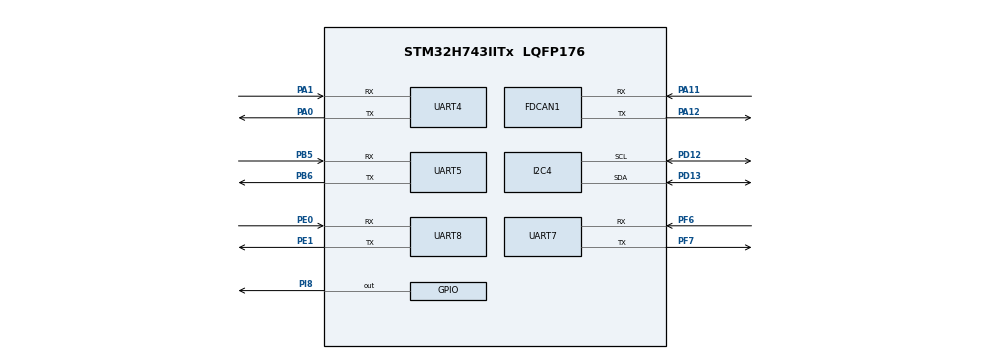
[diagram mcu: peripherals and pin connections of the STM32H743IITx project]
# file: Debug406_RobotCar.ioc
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CORTEX_M7.CPU_DCache=Disabled
CORTEX_M7.CPU_ICache=Disabled
Dma.Request0=UART4_TX
Dma.Request1=UART4_RX
Dma.UART4_RX.1.Direction=DMA_PERIPH_TO_MEMORY
Dma.UART4_RX.1.EventEnable=DISABLE
Dma.UART4_RX.1.FIFOMode=DMA_FIFOMODE_DISABLE
Dma.UART4_RX.1.Instance=DMA1_Stream1
Dma.UART4_RX.1.MemDataAlignment=DMA_MDATAALIGN_BYTE
Dma.UART4_RX.1.MemInc=DMA_MINC_ENABLE
Dma.UART4_RX.1.Mode=DMA_NORMAL
Dma.UART4_RX.1.PeriphDataAlignment=DMA_PDATAALIGN_BYTE
Dma.UART4_RX.1.PeriphInc=DMA_PINC_DISABLE
Dma.UART4_RX.1.Polarity=HAL_DMAMUX_REQ_GEN_RISING
Dma.UART4_RX.1.Priority=DMA_PRIORITY_LOW
Dma.UART4_RX.1.RequestNumber=1
Dma.UART4_RX.1.SignalID=NONE
Dma.UART4_RX.1.SyncEnable=DISABLE
Dma.UART4_RX.1.SyncPolarity=HAL_DMAMUX_SYNC_NO_EVENT
Dma.UART4_RX.1.SyncRequestNumber=1
Dma.UART4_RX.1.SyncSignalID=NONE
Dma.UART4_TX.0.Direction=DMA_MEMORY_TO_PERIPH
Dma.UART4_TX.0.EventEnable=DISABLE
Dma.UART4_TX.0.FIFOMode=DMA_FIFOMODE_DISABLE
Dma.UART4_TX.0.Instance=DMA1_Stream0
Dma.UART4_TX.0.MemDataAlignment=DMA_MDATAALIGN_BYTE
Dma.UART4_TX.0.MemInc=DMA_MINC_ENABLE
Dma.UART4_TX.0.Mode=DMA_NORMAL
Dma.UART4_TX.0.PeriphDataAlignment=DMA_PDATAALIGN_BYTE
Dma.UART4_TX.0.PeriphInc=DMA_PINC_DISABLE
Dma.UART4_TX.0.Polarity=HAL_DMAMUX_REQ_GEN_RISING
Dma.UART4_TX.0.Priority=DMA_PRIORITY_HIGH
Dma.UART4_TX.0.RequestNumber=1
Dma.UART4_TX.0.SignalID=NONE
Dma.UART4_TX.0.SyncEnable=DISABLE
Dma.UART4_TX.0.SyncPolarity=HAL_DMAMUX_SYNC_NO_EVENT
Dma.UART4_TX.0.SyncRequestNumber=1
Dma.UART4_TX.0.SyncSignalID=NONE
I2C4.Timing=0x307075B1
Mcu.Family=STM32H7
Mcu.Name=STM32H743IITx
Mcu.Package=LQFP176
NVIC.DMA1_Stream0_IRQn=true\:0\:0\:false\:false\:true\:false\:true
NVIC.DMA1_Stream1_IRQn=true\:0\:0\:false\:false\:true\:false\:true
NVIC.PriorityGroup=NVIC_PRIORITYGROUP_2
NVIC.UART4_IRQn=true\:0\:0\:false\:false\:true\:true\:true
NVIC.UART5_IRQn=true\:1\:1\:true\:false\:true\:true\:true
PA0.GPIO_Speed=GPIO_SPEED_FREQ_VERY_HIGH
PA0.Mode=Asynchronous
PA0.Signal=UART4_TX
PA1.GPIO_Speed=GPIO_SPEED_FREQ_VERY_HIGH
PA1.Mode=Asynchronous
PA1.Signal=UART4_RX
PA11.Mode=FDCAN_Activate
PA11.Signal=FDCAN1_RX
PA12.Mode=FDCAN_Activate
PA12.Signal=FDCAN1_TX
PA13\ (JTMS/SWDIO).Mode=Serial_Wire
PA13\ (JTMS/SWDIO).Signal=DEBUG_JTMS-SWDIO
PA14\ (JTCK/SWCLK).Mode=Serial_Wire
PA14\ (JTCK/SWCLK).Signal=DEBUG_JTCK-SWCLK
PB5.GPIO_Speed=GPIO_SPEED_FREQ_VERY_HIGH
PB5.Mode=Asynchronous
PB5.Signal=UART5_RX
PB6.GPIO_Speed=GPIO_SPEED_FREQ_VERY_HIGH
PB6.Mode=Asynchronous
PB6.Signal=UART5_TX
PD12.GPIO_Speed=GPIO_SPEED_FREQ_VERY_HIGH
PD12.Mode=I2C
PD12.Signal=I2C4_SCL
PD13.GPIO_Speed=GPIO_SPEED_FREQ_VERY_HIGH
PD13.Mode=I2C
PD13.Signal=I2C4_SDA
PE0.GPIO_Speed=GPIO_SPEED_FREQ_VERY_HIGH
PE0.Mode=Asynchronous
PE0.Signal=UART8_RX
PE1.GPIO_Speed=GPIO_SPEED_FREQ_VERY_HIGH
PE1.Mode=Asynchronous
PE1.Signal=UART8_TX
PF6.GPIO_Speed=GPIO_SPEED_FREQ_VERY_HIGH
PF6.Mode=Asynchronous
PF6.Signal=UART7_RX
PF7.GPIO_Speed=GPIO_SPEED_FREQ_VERY_HIGH
PF7.Mode=Asynchronous
PF7.Signal=UART7_TX
PH0-OSC_IN\ (PH0).Mode=HSE-External-Oscillator
PH0-OSC_IN\ (PH0).Signal=RCC_OSC_IN
PH1-OSC_OUT\ (PH1).Mode=HSE-External-Oscillator
PH1-OSC_OUT\ (PH1).Signal=RCC_OSC_OUT
PI8.GPIO_PuPd=GPIO_NOPULL
PI8.PinState=GPIO_PIN_RESET
PI8.Signal=GPIO_Output
ProjectManager.HeapSize=0x200
ProjectManager.StackSize=0x400
ProjectManager.TargetToolchain=MDK-ARM V5.27
RCC.ADCFreq_Value=30000000
RCC.APB1Freq_Value=120000000
RCC.APB2Freq_Value=120000000
RCC.APB3Freq_Value=120000000
RCC.APB4Freq_Value=120000000
RCC.CKPERSourceSelection=RCC_CLKPSOURCE_HSE
RCC.CortexFreq_Value=480000000
RCC.D1PPRE=RCC_APB3_DIV2
RCC.D2PPRE1=RCC_APB1_DIV2
RCC.D2PPRE2=RCC_APB2_DIV2
RCC.D3PPRE=RCC_APB4_DIV2
RCC.DIVM1=5
RCC.DIVM2=2
RCC.DIVN1=192
RCC.DIVN2=12
RCC.DIVP2=5
RCC.EnbaleCSS=true
RCC.FDCANCLockSelection=RCC_FDCANCLKSOURCE_PLL2
RCC.HCLKFreq_Value=240000000
RCC.HPRE=RCC_HCLK_DIV2
RCC.PLL2FRACN=0
RCC.PLL3FRACN=0
RCC.PLLFRACN=0
RCC.PLLSourceVirtual=RCC_PLLSOURCE_HSE
RCC.SYSCLKFreq_VALUE=480000000
RCC.SYSCLKSource=RCC_SYSCLKSOURCE_PLLCLK
RCC.USBFreq_Value=480000000
board=custom

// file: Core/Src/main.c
/* USER CODE BEGIN Header */
/**
  ******************************************************************************
  * @file           : main.c
  * @brief          : Main program body
  ******************************************************************************
  * @attention
  *
  * <h2><center>&copy; Copyright (c) 2020 STMicroelectronics.
  * All rights reserved.</center></h2>
  *
  * This software component is licensed by ST under BSD 3-Clause license,
  * the "License"; You may not use this file except in compliance with the
  * License. You may obtain a copy of the License at:
  *                        opensource.org/licenses/BSD-3-Clause
  *
  ******************************************************************************
  */
/* USER CODE END Header */
#include "main.h"
#include "dma.h"
#include "fdcan.h"
#include "i2c.h"
#include "usart.h"
#include "gpio.h"

void SystemClock_Config(void);

int main(void)
{

  /* MCU Configuration--------------------------------------------------------*/

  /* Reset of all peripherals, Initializes the Flash interface and the Systick. */
  HAL_Init();

  /* Configure the system clock */
  SystemClock_Config();

  /* Initialize all configured peripherals */
  MX_GPIO_Init();
  MX_DMA_Init();
  MX_UART4_Init();
  MX_UART5_Init();
  MX_UART7_Init();
  MX_I2C4_Init();
  MX_UART8_Init();
  MX_FDCAN1_Init();
  /* USER CODE BEGIN 2 */
	UserInit();
  /* USER CODE END 2 */

  /* Infinite loop */
  /* USER CODE BEGIN WHILE */
  while (1)
  {
		UserLoop();
    /* USER CODE END WHILE */

  }
}

void SystemClock_Config(void)
{
  RCC_OscInitTypeDef RCC_OscInitStruct = {0};
  RCC_ClkInitTypeDef RCC_ClkInitStruct = {0};

  /** Supply configuration update enable
  */
  HAL_PWREx_ConfigSupply(PWR_LDO_SUPPLY);
  /** Configure the main internal regulator output voltage
  */
  __HAL_PWR_VOLTAGESCALING_CONFIG(PWR_REGULATOR_VOLTAGE_SCALE0);

  while(!__HAL_PWR_GET_FLAG(PWR_FLAG_VOSRDY)) {}
  /** Macro to configure the PLL clock source
  */
  __HAL_RCC_PLL_PLLSOURCE_CONFIG(RCC_PLLSOURCE_HSE);
  /** Initializes the RCC Oscillators according to the specified parameters
  * in the RCC_OscInitTypeDef structure.
  */
  RCC_OscInitStruct.OscillatorType = RCC_OSCILLATORTYPE_HSE;
  RCC_OscInitStruct.HSEState = RCC_HSE_ON;
  RCC_OscInitStruct.PLL.PLLState = RCC_PLL_ON;
  RCC_OscInitStruct.PLL.PLLSource = RCC_PLLSOURCE_HSE;
  RCC_OscInitStruct.PLL.PLLM = 5;
  RCC_OscInitStruct.PLL.PLLN = 192;
  RCC_OscInitStruct.PLL.PLLP = 2;
  RCC_OscInitStruct.PLL.PLLQ = 2;
  RCC_OscInitStruct.PLL.PLLR = 2;
  RCC_OscInitStruct.PLL.PLLRGE = RCC_PLL1VCIRANGE_2;
  RCC_OscInitStruct.PLL.PLLVCOSEL = RCC_PLL1VCOWIDE;
  RCC_OscInitStruct.PLL.PLLFRACN = 0;
  if (HAL_RCC_OscConfig(&RCC_OscInitStruct) != HAL_OK)
  {
    Error_Handler();
  }
  /** Initializes the CPU, AHB and APB buses clocks
  */
  RCC_ClkInitStruct.ClockType = RCC_CLOCKTYPE_HCLK|RCC_CLOCKTYPE_SYSCLK
                              |RCC_CLOCKTYPE_PCLK1|RCC_CLOCKTYPE_PCLK2
                              |RCC_CLOCKTYPE_D3PCLK1|RCC_CLOCKTYPE_D1PCLK1;
  RCC_ClkInitStruct.SYSCLKSource = RCC_SYSCLKSOURCE_PLLCLK;
  RCC_ClkInitStruct.SYSCLKDivider = RCC_SYSCLK_DIV1;
  RCC_ClkInitStruct.AHBCLKDivider = RCC_HCLK_DIV2;
  RCC_ClkInitStruct.APB3CLKDivider = RCC_APB3_DIV2;
  RCC_ClkInitStruct.APB1CLKDivider = RCC_APB1_DIV2;
  RCC_ClkInitStruct.APB2CLKDivider = RCC_APB2_DIV2;
  RCC_ClkInitStruct.APB4CLKDivider = RCC_APB4_DIV2;

  if (HAL_RCC_ClockConfig(&RCC_ClkInitStruct, FLASH_LATENCY_4) != HAL_OK)
  {
    Error_Handler();
  }
  /** Enables the Clock Security System
  */
  HAL_RCC_EnableCSS();
}

void Error_Handler(void)
{
  __disable_irq();
  while (1)
  {
  }
}

/************************ (C) COPYRIGHT STMicroelectronics *****END OF FILE****/
